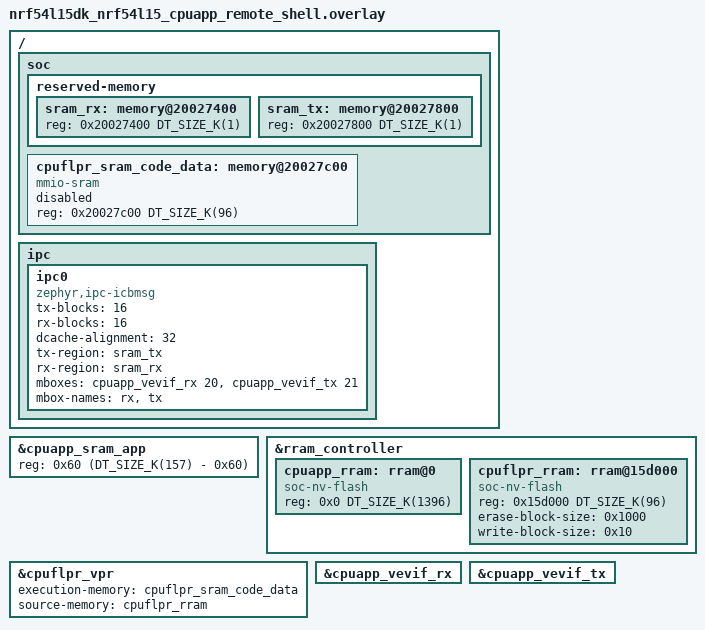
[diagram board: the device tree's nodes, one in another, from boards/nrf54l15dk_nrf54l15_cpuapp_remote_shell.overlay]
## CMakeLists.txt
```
# SPDX-License-Identifier: Apache-2.0

cmake_minimum_required(VERSION 3.28.0)
find_package(Zephyr REQUIRED HINTS $ENV{ZEPHYR_BASE})
project(shell_module)

target_sources(app PRIVATE src/main.c src/test_module.c)
target_sources_ifdef(CONFIG_SHELL_DYNAMIC_CMDS app PRIVATE src/dynamic_cmd.c)
target_sources_ifdef(CONFIG_SHELL_BACKEND_SERIAL app PRIVATE src/uart_reinit.c)
target_sources_ifdef(CONFIG_SHELL_START_OBSCURED app PRIVATE src/login_cmd.c)
```

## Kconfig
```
# Config options for logger sample app

# Copyright (c) 2018 Nordic Semiconductor ASA
# SPDX-License-Identifier: Apache-2.0

mainmenu "Shell module sample application"

menu "Application configuration"

config SHELL_FOREGROUND_CMDS
	bool "Shell foreground commands example"
	default y

config SHELL_DYNAMIC_CMDS
	bool "Shell dynamic commands example"
	default y

endmenu

source "Kconfig.zephyr"
```

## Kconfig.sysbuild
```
#
# Copyright (c) 2026 Nordic Semiconductor ASA
#
# SPDX-License-Identifier: Apache-2.0
#

config REMOTE_BOARD
	string
	default "$(BOARD)/nrf5340/cpunet" if BOARD_NRF5340DK_NRF5340_CPUAPP
	default "$(BOARD)/nrf5340/cpunet" if BOARD_NRF5340BSIM_NRF5340_CPUAPP
	default "$(BOARD)/nrf54h20/cpurad" if BOARD_NRF54H20DK_NRF54H20_CPUAPP
	default "$(BOARD)/nrf54l15/cpuflpr" if BOARD_NRF54L15DK_NRF54L15_CPUAPP

source "share/sysbuild/Kconfig"
```

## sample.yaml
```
sample:
  name: Shell Sample
tests:
  sample.shell.shell_module:
    platform_exclude: qemu_rx
    filter: CONFIG_SERIAL and dt_chosen_enabled("zephyr,shell-uart")
    tags: shell
    harness: shell
    min_ram: 40
    integration_platforms:
      - native_sim
    extra_configs:
      - arch:posix:CONFIG_UART_NATIVE_PTY_0_ON_STDINOUT=y
      - platform:iotdk/arc_iot:CONFIG_ARC_IOT_CUSTOM_CPU_IDLE=y
  sample.shell.shell_module.usb:
    depends_on: usbd
    tags:
      - shell
      - usb
    harness: keyboard
    min_ram: 40
    extra_args:
      - EXTRA_CONF_FILE="overlay-usb.conf"
      - DTC_OVERLAY_FILE="usb.overlay"
    integration_platforms:
      - frdm_k64f
  sample.shell.shell_module.minimal:
    filter: CONFIG_SERIAL and dt_chosen_enabled("zephyr,shell-uart")
    tags: shell
    harness: keyboard
    extra_args: CONF_FILE="prj_minimal.conf"
    integration_platforms:
      - native_sim
  sample.shell.shell_module.getopt:
    integration_platforms:
      - qemu_x86
    arch_exclude: posix
    filter: CONFIG_SERIAL and dt_chosen_enabled("zephyr,shell-uart") and not CONFIG_NEWLIB_LIBC
    tags: shell
    harness: keyboard
    min_ram: 40
    extra_args: CONF_FILE="prj_getopt.conf"
  sample.shell.shell_module.minimal_rtt:
    filter: CONFIG_HAS_SEGGER_RTT
    tags: shell
    harness: keyboard
    extra_args: CONF_FILE="prj_minimal_rtt.conf"
    integration_platforms:
      - nrf52833dk/nrf52833
  sample.shell.shell_module.bt:
    platform_allow:
      - nrf52840dk/nrf52840
    integration_platforms:
      - nrf52840dk/nrf52840
    tags:
      - shell
      - bluetooth
    filter: CONFIG_DT_HAS_ZEPHYR_NUS_UART_ENABLED
    harness: bluetooth_nus
    arch_exclude:
      - posix
    extra_args:
      - EXTRA_CONF_FILE="overlay-bt.conf"
      - DTC_OVERLAY_FILE="bt.overlay"
  sample.shell.shell_module.login:
    filter: CONFIG_SERIAL and dt_chosen_enabled("zephyr,shell-uart")
    tags: shell
    harness: keyboard
    min_ram: 40
    extra_args: CONF_FILE="prj_login.conf"
    integration_platforms:
      - native_sim
  sample.shell.shell_module.robot:
    harness: robot
    harness_config:
      robot_testsuite: shell_module.robot
  sample.shell.shell_module.remote:
    sysbuild: true
    tags:
      - shell
      - ipc
    platform_allow:
      - nrf54l15dk/nrf54l15/cpuapp
      - nrf5340dk/nrf5340/cpuapp
      - nrf5340bsim/nrf5340/cpuapp
      - nrf54h20dk/nrf54h20/cpuapp
    harness: shell
    harness_config:
      shell_commands_file: test_remote_shell.yml
    integration_platforms:
      - nrf5340bsim/nrf5340/cpuapp
    extra_configs:
      - CONFIG_IPC_SERVICE=y
      - CONFIG_MBOX=y
      - CONFIG_SHELL_REMOTE=y
      - CONFIG_PBUF_RX_READ_BUF_SIZE=256
      - CONFIG_HEAP_MEM_POOL_SIZE=1024
    extra_args:
      - FILE_SUFFIX=remote_shell
```

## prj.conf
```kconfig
CONFIG_PRINTK=y
CONFIG_SHELL=y
CONFIG_LOG=y
CONFIG_LOG_CMDS=y
CONFIG_INIT_STACKS=y
CONFIG_THREAD_STACK_INFO=y
CONFIG_KERNEL_SHELL=y
CONFIG_THREAD_MONITOR=y
CONFIG_BOOT_BANNER=n
CONFIG_THREAD_NAME=y
CONFIG_DEVICE_SHELL=y
CONFIG_DATE_SHELL=y
CONFIG_THREAD_RUNTIME_STATS=y
CONFIG_THREAD_RUNTIME_STATS_USE_TIMING_FUNCTIONS=y
CONFIG_STATS=y
CONFIG_STATS_SHELL=y
```

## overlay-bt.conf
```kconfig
CONFIG_SERIAL=y
CONFIG_CONSOLE=y
CONFIG_UART_CONSOLE=y

CONFIG_BT=y
CONFIG_BT_PERIPHERAL=y
CONFIG_BT_ZEPHYR_NUS=y
CONFIG_UART_BT=y
CONFIG_BT_ZEPHYR_NUS_AUTO_START_BLUETOOTH=y

# Bluetooth optimizations to allow larger data packets.
CONFIG_BT_RX_STACK_SIZE=2048
CONFIG_BT_L2CAP_TX_MTU=512
CONFIG_BT_BUF_ACL_RX_SIZE=502
CONFIG_BT_BUF_ACL_TX_SIZE=502
CONFIG_BT_CTLR_DATA_LENGTH_MAX=251
```

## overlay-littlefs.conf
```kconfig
CONFIG_FLASH=y
CONFIG_FLASH_MAP=y
CONFIG_FLASH_PAGE_LAYOUT=y

CONFIG_FILE_SYSTEM=y
CONFIG_FILE_SYSTEM_LITTLEFS=y
CONFIG_FILE_SYSTEM_SHELL=y
CONFIG_HEAP_MEM_POOL_SIZE=16384
```

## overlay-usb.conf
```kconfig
CONFIG_USB_DEVICE_STACK_NEXT=y
CONFIG_CDC_ACM_SERIAL_INITIALIZE_AT_BOOT=y
CONFIG_CDC_ACM_SERIAL_PRODUCT_STRING="Zephyr USB shell sample"
CONFIG_SHELL_BACKEND_SERIAL_CHECK_DTR=y
CONFIG_USBD_CDC_ACM_LOG_LEVEL_OFF=y
CONFIG_UART_LINE_CTRL=y
CONFIG_LOG_DEFAULT_LEVEL=1
```

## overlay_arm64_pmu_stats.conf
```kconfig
# SPDX-License-Identifier: Apache-2.0
#
# ARM64 PMU perf + SMP scheduler stats + PMU overflow sampling for shell_module.
#
# Build (from $ZEPHYR_BASE):
#
#   west build -p always -b versalnet_apu samples/subsys/shell/shell_module \
#     -- -DEXTRA_CONF_FILE=overlay_arm64_pmu_stats.conf
#
# Shell commands:
#   sched cpus | sched threads | sched top [-c cpu] [-d] [-i ms]
#   perf list | perf start [-e ev] | perf stop | perf report
#   perf record start [-e ev] [-f Hz] [-t sec] | stop | dump | export | clear

CONFIG_SHELL_BACKEND_SERIAL=y
CONFIG_MAIN_STACK_SIZE=4096
CONFIG_SHELL_STACK_SIZE=4096

# Prevent deferred log messages from crashing the logging thread via the
# shell log backend's cbprintf path on SMP.  With LOG_MODE_DEFERRED (the
# default) and SHELL_LOG_BACKEND, the logging thread can corrupt its own
# saved LR with the uart device's .rodata address when processing messages
# that include 64-bit format args.  Immediate mode prints synchronously on
# the calling thread and avoids the logging thread entirely.
CONFIG_LOG_MODE_IMMEDIATE=y

CONFIG_ARM64_PMUV3=y
CONFIG_PERF_SHELL=y

CONFIG_PROFILING=y
CONFIG_PROFILING_PMU_SAMPLING=y

CONFIG_THREAD_RUNTIME_STATS=y
CONFIG_SCHED_THREAD_USAGE=y
CONFIG_SCHED_THREAD_USAGE_ALL=y
CONFIG_SCHED_THREAD_USAGE_AUTO_ENABLE=y
CONFIG_THREAD_MONITOR=y
CONFIG_THREAD_NAME=y
CONFIG_SCHED_STATS_SHELL=y

CONFIG_SMP=y
CONFIG_SCHED_CPU_MASK=y
```

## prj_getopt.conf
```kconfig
CONFIG_PRINTK=y
CONFIG_SHELL=y
CONFIG_SHELL_GETOPT=y
CONFIG_LOG=y
CONFIG_INIT_STACKS=y
CONFIG_THREAD_STACK_INFO=y
CONFIG_KERNEL_SHELL=y
CONFIG_THREAD_MONITOR=y
CONFIG_BOOT_BANNER=n
CONFIG_THREAD_NAME=y
CONFIG_DEVICE_SHELL=y
CONFIG_DATE_SHELL=y
CONFIG_THREAD_RUNTIME_STATS=y
```

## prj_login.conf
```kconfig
CONFIG_PRINTK=y
CONFIG_SHELL=y
CONFIG_LOG=y
CONFIG_INIT_STACKS=y
CONFIG_THREAD_STACK_INFO=y
CONFIG_KERNEL_SHELL=y
CONFIG_THREAD_MONITOR=y
CONFIG_BOOT_BANNER=n
CONFIG_THREAD_NAME=y
CONFIG_DEVICE_SHELL=y
CONFIG_DATE_SHELL=y
CONFIG_THREAD_RUNTIME_STATS=y

CONFIG_SHELL_CMDS_SELECT=y
CONFIG_SHELL_START_OBSCURED=y
CONFIG_SHELL_PROMPT_UART="login: "
CONFIG_SHELL_CMD_ROOT="login"
```

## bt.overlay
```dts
/*
 * Copyright (c) 2024 Croxel, Inc.
 *
 * SPDX-License-Identifier: Apache-2.0
 */

/ {
	chosen {
		zephyr,console = &bt_nus_console_uart;
		zephyr,shell-uart = &bt_nus_console_uart;
	};

	bt_nus_console_uart: bt_nus_console_uart {
		compatible = "zephyr,nus-uart";
		rx-fifo-size = <1024>;
		tx-fifo-size = <1024>;
	};
};
```

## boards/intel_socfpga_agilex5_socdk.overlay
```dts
/*
 * Copyright (C) 2023 Intel Corporation
 * SPDX-License-Identifier: Apache-2.0
 */

/*
 * The overlay file should be used to enable any
 * dts nodes required by this shell application for this
 * board.
 *
 * Nothing here as of now.
 */

&timer0 {
	status = "okay";
};

&timer1 {
	status = "okay";
};

&timer2 {
	status = "okay";
};

&timer3 {
	status = "okay";
};

&sip_smc {
	zephyr,num-clients = <2>;
	status = "okay";
};

&sdmmc {
	status = "okay";
};
```

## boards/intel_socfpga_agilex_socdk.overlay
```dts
/*
 * Copyright (C) 2023 Intel Corporation
 * SPDX-License-Identifier: Apache-2.0
 */

/*
 * The overlay file should be used to enable any
 * dts nodes required by this shell application for this
 * board.
 */

&sip_smc {
	zephyr,num-clients = <2>;
	status = "okay";
};
```

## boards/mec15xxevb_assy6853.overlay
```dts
/ {
    chosen {
        zephyr,console = &uart2;
        zephyr,shell-uart = &uart2;
    };
};
```

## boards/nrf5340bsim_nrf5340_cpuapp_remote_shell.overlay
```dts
/*
 * Copyright (c) 2026 Nordic Semiconductor ASA
 *
 * SPDX-License-Identifier: Apache-2.0
 */

#include "nrf5340dk_nrf5340_cpuapp_remote_shell.overlay"

/ {
	chosen {
		zephyr,console = &uart0;
		zephyr,shell-uart = &uart0;
	};
};

&uart0 {
	compatible = "zephyr,native-pty-uart";
	status = "okay";
	/delete-property/ pinctrl-0;
	/delete-property/ pinctrl-1;
	/delete-property/ pinctrl-names;
};
```

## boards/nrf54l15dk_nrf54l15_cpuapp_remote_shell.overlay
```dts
/*
 * Copyright (c) 2026 Nordic Semiconductor ASA
 *
 * SPDX-License-Identifier: Apache-2.0
 */

/* 256k RAM layout:
 *  - 157k APP RAM
 *  - 2k APP-FLPR IPC communication
 *  - 96k FLPR Code
 *  - 1k FLPR Hibernation space
 */

/ {
	soc {
		reserved-memory {
			#address-cells = <1>;
			#size-cells = <1>;

			sram_rx: memory@20027400 {
				reg = <0x20027400 DT_SIZE_K(1)>;
			};

			sram_tx: memory@20027800 {
				reg = <0x20027800 DT_SIZE_K(1)>;
			};
		};

		cpuflpr_sram_code_data: memory@20027c00 {
			compatible = "mmio-sram";
			reg = <0x20027c00 DT_SIZE_K(96)>;
			ranges = <0x0 0x20027c00 DT_SIZE_K(96)>;
			status = "reserved";
			#address-cells = <1>;
			#size-cells = <1>;
		};
	};

	ipc {
		ipc0: ipc0 {
			compatible = "zephyr,ipc-icbmsg";
			tx-blocks = <16>;
			rx-blocks = <16>;
			dcache-alignment = <32>;
			tx-region = <&sram_tx>;
			rx-region = <&sram_rx>;
			mboxes = <&cpuapp_vevif_rx 20>, <&cpuapp_vevif_tx 21>;
			mbox-names = "rx", "tx";
			status = "okay";
		};
	};
};

&cpuapp_sram_app {
	reg = <0x60 (DT_SIZE_K(157) - 0x60)>;
};

&rram_controller {
	cpuapp_rram: rram@0 {
		compatible = "soc-nv-flash";
		reg = <0x0 DT_SIZE_K(1396)>;
		ranges = <0x0 0 DT_SIZE_K(1396)>;
	};

	cpuflpr_rram: rram@15d000 {
		compatible = "soc-nv-flash";
		reg = <0x15d000 DT_SIZE_K(96)>;
		ranges = <0x0 0x15d000 DT_SIZE_K(96)>;
		erase-block-size = <0x1000>;
		write-block-size = <0x10>;
		#address-cells = <1>;
		#size-cells = <1>;
	};
};

&cpuflpr_vpr {
	status = "okay";
	execution-memory = <&cpuflpr_sram_code_data>;
	source-memory = <&cpuflpr_rram>;
};

&cpuapp_vevif_rx {
	status = "okay";
};

&cpuapp_vevif_tx {
	status = "okay";
};
```

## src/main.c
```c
/*
 * Copyright (c) 2015 Intel Corporation
 *
 * SPDX-License-Identifier: Apache-2.0
 */

#include <zephyr/kernel.h>
#include <zephyr/shell/shell.h>
#include <zephyr/version.h>
#include <zephyr/logging/log.h>
#include <stdlib.h>
#include <zephyr/drivers/uart.h>
#include <ctype.h>

LOG_MODULE_REGISTER(app);

extern void foo(void);

void timer_expired_handler(struct k_timer *timer)
{
	LOG_INF("Timer expired.");

	/* Call another module to present logging from multiple sources. */
	foo();
}

K_TIMER_DEFINE(log_timer, timer_expired_handler, NULL);

static int cmd_log_test_start(const struct shell *sh, size_t argc,
			      char **argv, uint32_t period)
{
	ARG_UNUSED(argv);

	k_timer_start(&log_timer, K_MSEC(period), K_MSEC(period));
	shell_print(sh, "Log test started\n");

	return 0;
}

static int cmd_log_test_start_demo(const struct shell *sh, size_t argc,
				   char **argv)
{
	return cmd_log_test_start(sh, argc, argv, 200);
}

static int cmd_log_test_start_flood(const struct shell *sh, size_t argc,
				    char **argv)
{
	return cmd_log_test_start(sh, argc, argv, 10);
}

static int cmd_log_test_stop(const struct shell *sh, size_t argc,
			     char **argv)
{
	ARG_UNUSED(argc);
	ARG_UNUSED(argv);

	k_timer_stop(&log_timer);
	shell_print(sh, "Log test stopped");

	return 0;
}

SHELL_STATIC_SUBCMD_SET_CREATE(sub_log_test_start,
	SHELL_CMD_ARG(demo, NULL,
		  "Start log timer which generates log message every 200ms.",
		  cmd_log_test_start_demo, 1, 0),
	SHELL_CMD_ARG(flood, NULL,
		  "Start log timer which generates log message every 10ms.",
		  cmd_log_test_start_flood, 1, 0),
	SHELL_SUBCMD_SET_END /* Array terminated. */
);
SHELL_STATIC_SUBCMD_SET_CREATE(sub_log_test,
	SHELL_CMD_ARG(start, &sub_log_test_start, "Start log test", NULL, 2, 0),
	SHELL_CMD_ARG(stop, NULL, "Stop log test.", cmd_log_test_stop, 1, 0),
	SHELL_SUBCMD_SET_END /* Array terminated. */
);

SHELL_CMD_REGISTER(log_test, &sub_log_test, "Log test", NULL);

static int cmd_demo_ping(const struct shell *sh, size_t argc, char **argv)
{
	ARG_UNUSED(argc);
	ARG_UNUSED(argv);

	shell_print(sh, "pong");

	return 0;
}

static int cmd_demo_board(const struct shell *sh, size_t argc, char **argv)
{
	ARG_UNUSED(argc);
	ARG_UNUSED(argv);

	shell_print(sh, CONFIG_BOARD);

	return 0;
}

#if defined CONFIG_SHELL_GETOPT
/* Thread save usage */
static int cmd_demo_getopt_ts(const struct shell *sh, size_t argc,
			      char **argv)
{
	struct sys_getopt_state *state;
	char *cvalue = NULL;
	int aflag = 0;
	int bflag = 0;
	int c;

	while ((c = sys_getopt(argc, argv, "abhc:")) != -1) {
		state = sys_getopt_state_get();
		switch (c) {
		case 'a':
			aflag = 1;
			break;
		case 'b':
			bflag = 1;
			break;
		case 'c':
			cvalue = state->optarg;
			break;
		case 'h':
			/* When getopt is active shell is not parsing
			 * command handler to print help message. It must
			 * be done explicitly.
			 */
			shell_help(sh);
			return SHELL_CMD_HELP_PRINTED;
		case '?':
			if (state->optopt == 'c') {
				shell_print(sh,
					"Option -%c requires an argument.",
					state->optopt);
			} else if (isprint(state->optopt) != 0) {
				shell_print(sh,
					"Unknown option `-%c'.",
					state->optopt);
			} else {
				shell_print(sh,
					"Unknown option character `\\x%x'.",
					state->optopt);
			}
			return 1;
		default:
			break;
		}
	}

	shell_print(sh, "aflag = %d, bflag = %d", aflag, bflag);
	return 0;
}

static int cmd_demo_getopt(const struct shell *sh, size_t argc,
			      char **argv)
{
	char *cvalue = NULL;
	int aflag = 0;
	int bflag = 0;
	int c;

	while ((c = sys_getopt(argc, argv, "abhc:")) != -1) {
		switch (c) {
		case 'a':
			aflag = 1;
			break;
		case 'b':
			bflag = 1;
			break;
		case 'c':
			cvalue = sys_getopt_optarg;
			break;
		case 'h':
			/* When getopt is active shell is not parsing
			 * command handler to print help message. It must
			 * be done explicitly.
			 */
			shell_help(sh);
			return SHELL_CMD_HELP_PRINTED;
		case '?':
			if (sys_getopt_optopt == 'c') {
				shell_print(sh,
					"Option -%c requires an argument.",
					sys_getopt_optopt);
			} else if (isprint(sys_getopt_optopt) != 0) {
				shell_print(sh, "Unknown option `-%c'.",
					    sys_getopt_optopt);
			} else {
				shell_print(sh,
					"Unknown option character `\\x%x'.",
					sys_getopt_optopt);
			}
			return 1;
		default:
			break;
		}
	}

	shell_print(sh, "aflag = %d, bflag = %d", aflag, bflag);
	return 0;
}
#endif

static int cmd_demo_params(const struct shell *sh, size_t argc, char **argv)
{
	shell_print(sh, "argc = %zd", argc);
	for (size_t cnt = 0; cnt < argc; cnt++) {
		shell_print(sh, "  argv[%zd] = %s", cnt, argv[cnt]);
	}

	return 0;
}

static int cmd_demo_hexdump(const struct shell *sh, size_t argc, char **argv)
{
	shell_print(sh, "argc = %zd", argc);
	for (size_t cnt = 0; cnt < argc; cnt++) {
		shell_print(sh, "argv[%zd]", cnt);
		shell_hexdump(sh, (const uint8_t *)argv[cnt], strlen(argv[cnt]));
	}

	return 0;
}

static int cmd_version(const struct shell *sh, size_t argc, char **argv)
{
	ARG_UNUSED(argc);
	ARG_UNUSED(argv);

	shell_print(sh, "Zephyr version %s", KERNEL_VERSION_STRING);

	return 0;
}

static int set_bypass(const struct shell *sh, shell_bypass_cb_t bypass)
{
	static bool in_use;

	if (bypass && in_use) {
		shell_error(sh, "Sample supports setting bypass on single instance.");

		return -EBUSY;
	}

	in_use = !in_use;
	if (in_use) {
		shell_print(sh, "Bypass started, press ctrl-x ctrl-q to escape");
		in_use = true;
	}

	shell_set_bypass(sh, bypass, NULL);

	return 0;
}

#define CHAR_1 0x18
#define CHAR_2 0x11

static void bypass_cb(const struct shell *sh, uint8_t *data, size_t len, void *user_data)
{
	static uint8_t tail;
	bool escape = false;

	ARG_UNUSED(user_data);

	/* Check if escape criteria is met. */
	if (tail == CHAR_1 && data[0] == CHAR_2) {
		escape = true;
	} else {
		for (int i = 0; i < (len - 1); i++) {
			if (data[i] == CHAR_1 && data[i + 1] == CHAR_2) {
				escape = true;
				break;
			}
		}
	}

	if (escape) {
		shell_print(sh, "Exit bypass");
		set_bypass(sh, NULL);
		tail = 0;
		return;
	}

	/* Store last byte for escape sequence detection */
	tail = data[len - 1];

	/* Do the data processing. */
	for (int i = 0; i < len; i++) {
		shell_fprintf(sh, SHELL_INFO, "%02x ", data[i]);
	}
	shell_fprintf(sh, SHELL_INFO, "| ");

	for (int i = 0; i < len; i++) {
		shell_fprintf(sh, SHELL_INFO, "%c", data[i]);
	}
	shell_fprintf(sh, SHELL_INFO, "\n");

}

static int cmd_bypass(const struct shell *sh, size_t argc, char **argv)
{
	return set_bypass(sh, bypass_cb);
}

static int cmd_demo_readline(const struct shell *sh, size_t argc, char **argv)
{
	uint8_t input_buf[256];
	int ret;

	if (argc == 2 && strcmp(argv[1], "obscured") == 0) {
		shell_obscure_set(sh, true);
	}

	shell_readline_prompt_set(sh, "Input: ");
	ret = shell_readline(sh, input_buf, sizeof(input_buf), K_SECONDS(10));
	shell_obscure_set(sh, false);

	if (ret < 0) {
		shell_error(sh, "Input error (%d)", ret);
		return ret;
	}

	shell_print(sh, "Got %d characters:", ret);
	shell_hexdump(sh, input_buf, ret);

	return 0;
}

static int cmd_dict(const struct shell *sh, size_t argc, char **argv,
		    void *data)
{
	int val = (intptr_t)data;

	shell_print(sh, "(syntax, value) : (%s, %d)", argv[0], val);

	return 0;
}

SHELL_SUBCMD_DICT_SET_CREATE(sub_dict_cmds, cmd_dict,
	(value_0, 0, "value 0"), (value_1, 1, "value 1"),
	(value_2, 2, "value 2"), (value_3, 3, "value 3")
);

SHELL_STATIC_SUBCMD_SET_CREATE(sub_demo,
	SHELL_CMD(dictionary, &sub_dict_cmds, "Dictionary commands", NULL),
	SHELL_CMD(hexdump, NULL, "Hexdump params command.", cmd_demo_hexdump),
	SHELL_CMD(params, NULL, "Print params command.", cmd_demo_params),
	SHELL_CMD(ping, NULL, "Ping command.", cmd_demo_ping),
	SHELL_CMD(board, NULL, "Show board name command.", cmd_demo_board),
	SHELL_COND_CMD_ARG(COND_CODE_1(CONFIG_SHELL_REMOTE_CLI, (0), (1)),
			readline, NULL, SHELL_HELP("Read user input", "[obscured]"),
		      cmd_demo_readline, 1, 1),
#if defined CONFIG_SHELL_GETOPT
	SHELL_CMD(getopt_thread_safe, NULL,
		  "Command using getopt in thread safe way"
		  " looking for: \"abhc:\".",
		  cmd_demo_getopt_ts),
	SHELL_CMD(getopt, NULL, "Command using getopt in non thread safe way"
		  " looking for: \"abhc:\".\n", cmd_demo_getopt),
#endif
	SHELL_SUBCMD_SET_END /* Array terminated. */
);
SHELL_CMD_REGISTER(demo, &sub_demo, "Demo commands", NULL);

SHELL_CMD_ARG_REGISTER(version, NULL, "Show kernel version", cmd_version, 1, 0);

SHELL_COND_CMD_ARG_REGISTER(COND_CODE_1(CONFIG_SHELL_REMOTE_CLI, (0), (1)),
			bypass, NULL, "Bypass shell", cmd_bypass, 1, 0);

/* Create a set of commands. Commands to this set are added using @ref SHELL_SUBCMD_ADD
 * and @ref SHELL_SUBCMD_COND_ADD.
 */
SHELL_SUBCMD_SET_CREATE(sub_section_cmd, (section_cmd));

static int cmd1_handler(const struct shell *sh, size_t argc, char **argv)
{
	ARG_UNUSED(sh);
	ARG_UNUSED(argc);
	ARG_UNUSED(argv);

	shell_print(sh, "cmd1 executed");

	return 0;
}

/* Create a set of subcommands for "section_cmd cm1". */
SHELL_SUBCMD_SET_CREATE(sub_section_cmd1, (section_cmd, cmd1));

/* Add command to the set. Subcommand set is identify by parent shell command. */
SHELL_SUBCMD_ADD((section_cmd), cmd1, &sub_section_cmd1, "help for cmd1", cmd1_handler, 1, 0);

SHELL_CMD_REGISTER(section_cmd, &sub_section_cmd,
		   "Demo command using section for subcommand registration", NULL);

int main(void)
{
#if DT_NODE_HAS_COMPAT(DT_CHOSEN(zephyr_shell_uart), zephyr_cdc_acm_uart)
	const struct device *dev;
	uint32_t dtr = 0;

	dev = DEVICE_DT_GET(DT_CHOSEN(zephyr_shell_uart));
	if (!device_is_ready(dev)) {
		return 0;
	}

	while (!dtr) {
		uart_line_ctrl_get(dev, UART_LINE_CTRL_DTR, &dtr);
		k_sleep(K_MSEC(100));
	}
#endif
	return 0;
}
```

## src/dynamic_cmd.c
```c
/*
 * Copyright (c) 2018 Nordic Semiconductor ASA
 *
 * SPDX-License-Identifier: Apache-2.0
 */

#include <zephyr/shell/shell.h>
#include <ctype.h>
#include <stdio.h>
#include <stdlib.h>

#define MAX_CMD_CNT (20u)
#define MAX_CMD_LEN (33u)

/* buffer holding dynamically created user commands */
static char dynamic_cmd_buffer[MAX_CMD_CNT][MAX_CMD_LEN];
/* commands counter */
static uint8_t dynamic_cmd_cnt;

typedef int cmp_t(const void *, const void *);
extern void qsort(void *a, size_t n, size_t es, cmp_t *cmp);

/* function required by qsort */
static int string_cmp(const void *p_a, const void *p_b)
{
	return strcmp((const char *)p_a, (const char *)p_b);
}

static int cmd_dynamic_add(const struct shell *sh,
			   size_t argc, char **argv)
{
	uint16_t cmd_len;
	uint8_t idx;

	ARG_UNUSED(argc);

	if (dynamic_cmd_cnt >= MAX_CMD_CNT) {
		shell_error(sh, "command limit reached");
		return -ENOEXEC;
	}

	cmd_len = strlen(argv[1]);

	if (cmd_len >= MAX_CMD_LEN) {
		shell_error(sh, "too long command");
		return -ENOEXEC;
	}

	for (idx = 0U; idx < cmd_len; idx++) {
		if (isalnum((int)(argv[1][idx])) == 0) {
			shell_error(sh,
				    "bad command name - please use only"
				    " alphanumerical characters");
			return -ENOEXEC;
		}
	}

	for (idx = 0U; idx < MAX_CMD_CNT; idx++) {
		if (!strcmp(dynamic_cmd_buffer[idx], argv[1])) {
			shell_error(sh, "duplicated command");
			return -ENOEXEC;
		}
	}

	sprintf(dynamic_cmd_buffer[dynamic_cmd_cnt++], "%s", argv[1]);

	qsort(dynamic_cmd_buffer, dynamic_cmd_cnt,
	      sizeof(dynamic_cmd_buffer[0]), string_cmp);

	shell_print(sh, "command added successfully");

	return 0;
}

static int cmd_dynamic_execute(const struct shell *sh,
			       size_t argc, char **argv)
{
	ARG_UNUSED(argc);
	ARG_UNUSED(argv);

	for (uint8_t idx = 0; idx <  dynamic_cmd_cnt; idx++) {
		if (!strcmp(dynamic_cmd_buffer[idx], argv[1])) {
			shell_print(sh, "dynamic command: %s", argv[1]);
			return 0;
		}
	}

	shell_error(sh, "%s: unknown parameter: %s", argv[0], argv[1]);

	return -ENOEXEC;
}

static int cmd_dynamic_remove(const struct shell *sh, size_t argc,
			      char **argv)
{
	ARG_UNUSED(argc);
	ARG_UNUSED(argv);

	for (uint8_t idx = 0; idx <  dynamic_cmd_cnt; idx++) {
		if (!strcmp(dynamic_cmd_buffer[idx], argv[1])) {
			if (idx == MAX_CMD_CNT - 1) {
				dynamic_cmd_buffer[idx][0] = '\0';
			} else {
				memmove(dynamic_cmd_buffer[idx],
					dynamic_cmd_buffer[idx + 1],
					sizeof(dynamic_cmd_buffer[idx]) *
					(dynamic_cmd_cnt - idx));
			}

			--dynamic_cmd_cnt;
			shell_print(sh, "command removed successfully");
			return 0;
		}
	}
	shell_error(sh, "did not find command: %s", argv[1]);

	return -ENOEXEC;
}

static int cmd_dynamic_show(const struct shell *sh,
			    size_t argc, char **argv)
{
	ARG_UNUSED(argc);
	ARG_UNUSED(argv);

	if (dynamic_cmd_cnt == 0U) {
		shell_warn(sh, "Please add some commands first.");
		return -ENOEXEC;
	}

	shell_print(sh, "Dynamic command list:");

	for (uint8_t i = 0; i < dynamic_cmd_cnt; i++) {
		shell_print(sh, "[%3d] %s", i, dynamic_cmd_buffer[i]);
	}

	return 0;
}

/* dynamic command creation */
static void dynamic_cmd_get(size_t idx, struct shell_static_entry *entry)
{
	if (idx < dynamic_cmd_cnt) {
		/* m_dynamic_cmd_buffer must be sorted alphabetically to ensure
		 * correct CLI completion
		 */
		entry->syntax = dynamic_cmd_buffer[idx];
		entry->handler  = NULL;
		entry->subcmd = NULL;
		entry->help = "Show dynamic command name.";
	} else {
		/* if there are no more dynamic commands available syntax
		 * must be set to NULL.
		 */
		entry->syntax = NULL;
	}
}

SHELL_DYNAMIC_CMD_CREATE(m_sub_dynamic_set, dynamic_cmd_get);
SHELL_STATIC_SUBCMD_SET_CREATE(m_sub_dynamic,
	SHELL_CMD_ARG(add, NULL,
		"Add a new dynamic command.\nExample usage: [ dynamic add test "
		"] will add a dynamic command 'test'.\nIn this example, command"
		" name length is limited to 32 chars. You can add up to 20"
		" commands. Commands are automatically sorted to ensure correct"
		" shell completion.",
		cmd_dynamic_add, 2, 0),
	SHELL_CMD_ARG(execute, &m_sub_dynamic_set,
		"Execute a command.", cmd_dynamic_execute, 2, 0),
	SHELL_CMD_ARG(remove, &m_sub_dynamic_set,
		"Remove a command.", cmd_dynamic_remove, 2, 0),
	SHELL_CMD_ARG(show, NULL,
		"Show all added dynamic commands.", cmd_dynamic_show, 1, 0),
	SHELL_SUBCMD_SET_END
);

SHELL_CMD_REGISTER(dynamic, &m_sub_dynamic,
		   "Demonstrate dynamic command usage.", NULL);
```

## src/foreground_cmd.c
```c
/*
 * Copyright (c) 2018 Nordic Semiconductor ASA
 *
 * SPDX-License-Identifier: Apache-2.0
 */

#include <shell/shell.h>
#include <zephyr.h>

#define FOREGROUND_TIMER_HELP \
	"Demo command showing printing to shell from various contexts"

#define FOREGROUND_TIMER_START_HELP \
	"Start periodic timer. Timer handler prints to shell. CTRL+C" \
	" terminates printing. Timer keeps running in background."

#define FOREGROUND_TIMER_STOP_HELP \
	"Stop timer."

#define FOREGROUND_TIMER_SINGLE_SHOT_HELP \
	"Start single shot timer."

struct timer_work_duo {
	struct k_timer timer;
	struct k_work work;
	const struct shell *shell;
	bool single_shot;
	bool running;
};

static struct timer_work_duo data;

static void timer_expired_work(struct k_work *work)
{
	struct timer_work_duo *data =
			CONTAINER_OF(work, struct timer_work_duo, work);

	shell_print(data->shell, "Timer expired.");

	if (data->single_shot) {
		shell_print(data->shell, "Single shot timer command exits.");
		shell_command_exit(data->shell);
		data->running = false;
	}
}

static void timer_handler(struct k_timer *timer)
{
	struct timer_work_duo *data =
			CONTAINER_OF(timer, struct timer_work_duo, timer);

	k_work_submit(&data->work);
}

static int start_timer(const struct shell *shell, bool single_shot)
{

	if (data.running) {
		shell_error(shell, "Timer is already started.");
		return -ENOEXEC;
	}

	k_timer_init(&data.timer, timer_handler, NULL);
	k_work_init(&data.work, timer_expired_work);
	data.shell = shell;
	data.single_shot = single_shot;
	data.running = true;

	k_timer_start(&data.timer, 1000, single_shot ? 0 : 1000);

	shell_command_enter(shell);

	return 0;

}
static int cmd_fg_timer_start(const struct shell *shell,
			      size_t argc, char **argv)
{
	ARG_UNUSED(argc);
	ARG_UNUSED(argv);

	int err;

	err = start_timer(shell, false);

	if (err == 0) {
		shell_print(shell, "Periodic timer started.");
	}

	return err;
}

static int cmd_fg_timer_single_shot(const struct shell *shell,
				    size_t argc, char **argv)
{
	ARG_UNUSED(argc);
	ARG_UNUSED(argv);

	int err;

	err = start_timer(shell, true);

	if (err == 0) {
		shell_print(shell, "Single shot started.");
	}

	return err;
}

static int cmd_fg_timer_stop(const struct shell *shell,
			      size_t argc, char **argv)
{
	ARG_UNUSED(argc);
	ARG_UNUSED(argv);

	k_timer_stop(&data.timer);
	data.running = false;

	shell_print(shell, "Timer stopped.");

	return 0;
}

SHELL_CREATE_STATIC_SUBCMD_SET(sub_foreground_timer)
{
	/* Alphabetically sorted. */
	SHELL_CMD_ARG(start, NULL, FOREGROUND_TIMER_START_HELP,
			cmd_fg_timer_start, 1, 0),
	SHELL_CMD_ARG(stop, NULL, FOREGROUND_TIMER_STOP_HELP,
			cmd_fg_timer_stop, 1, 0),
	SHELL_CMD_ARG(single_shot, NULL, FOREGROUND_TIMER_SINGLE_SHOT_HELP,
			cmd_fg_timer_single_shot, 1, 0),
	SHELL_SUBCMD_SET_END /* Array terminated. */
};

SHELL_CMD_ARG_REGISTER(foreground_timer, &sub_foreground_timer,
		   FOREGROUND_TIMER_HELP, NULL, 1, 1);
```

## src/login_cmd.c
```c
/*
 * Copyright (c) 2015 Intel Corporation
 *
 * SPDX-License-Identifier: Apache-2.0
 */

#include <zephyr/kernel.h>
#include <zephyr/shell/shell.h>
#include <zephyr/init.h>

#define DEFAULT_PASSWORD "zephyr"

static int login_init(void)
{
	printk("Shell Login Demo\nHint: password = %s\n", DEFAULT_PASSWORD);
	if (!CONFIG_SHELL_CMD_ROOT[0]) {
		shell_set_root_cmd("login");
	}
	return 0;
}

static int check_passwd(char *passwd)
{
	/* example only -- not recommended for production use */
	return strcmp(passwd, DEFAULT_PASSWORD);
}

static int cmd_login(const struct shell *sh, size_t argc, char **argv)
{
	static uint32_t attempts;

	if (check_passwd(argv[1]) != 0) {
		shell_error(sh, "Incorrect password!");
		attempts++;
		if (attempts > 3) {
			k_sleep(K_SECONDS(attempts));
		}
		return -EINVAL;
	}

	/* clear history so password not visible there */
	z_shell_history_purge(sh->history);
	shell_obscure_set(sh, false);
	shell_set_root_cmd(NULL);
	shell_prompt_change(sh, "uart:~$ ");
	shell_print(sh, "Shell Login Demo\n");
	shell_print(sh, "Hit tab for help.\n");
	attempts = 0;
	return 0;
}

static int cmd_logout(const struct shell *sh, size_t argc, char **argv)
{
	shell_set_root_cmd("login");
	shell_obscure_set(sh, true);
	shell_prompt_change(sh, "login: ");
	shell_print(sh, "\n");
	return 0;
}

SHELL_CMD_ARG_REGISTER(login, NULL, "<password>", cmd_login, 2, 0);

SHELL_CMD_REGISTER(logout, NULL, "Log out.", cmd_logout);

SYS_INIT(login_init, APPLICATION, CONFIG_APPLICATION_INIT_PRIORITY);
```

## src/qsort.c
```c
/*-
 * SPDX-License-Identifier: BSD-3-Clause
 *
 * Copyright (c) 1992, 1993
 *	The Regents of the University of California.  All rights reserved.
 *
 * Redistribution and use in source and binary forms, with or without
 * modification, are permitted provided that the following conditions
 * are met:
 * 1. Redistributions of source code must retain the above copyright
 *    notice, this list of conditions and the following disclaimer.
 * 2. Redistributions in binary form must reproduce the above copyright
 *    notice, this list of conditions and the following disclaimer in the
 *    documentation and/or other materials provided with the distribution.
 * 3. Neither the name of the University nor the names of its contributors
 *    may be used to endorse or promote products derived from this software
 *    without specific prior written permission.
 *
 * THIS SOFTWARE IS PROVIDED BY THE REGENTS AND CONTRIBUTORS ``AS IS'' AND
 * ANY EXPRESS OR IMPLIED WARRANTIES, INCLUDING, BUT NOT LIMITED TO, THE
 * IMPLIED WARRANTIES OF MERCHANTABILITY AND FITNESS FOR A PARTICULAR PURPOSE
 * ARE DISCLAIMED.  IN NO EVENT SHALL THE REGENTS OR CONTRIBUTORS BE LIABLE
 * FOR ANY DIRECT, INDIRECT, INCIDENTAL, SPECIAL, EXEMPLARY, OR CONSEQUENTIAL
 * DAMAGES (INCLUDING, BUT NOT LIMITED TO, PROCUREMENT OF SUBSTITUTE GOODS
 * OR SERVICES; LOSS OF USE, DATA, OR PROFITS; OR BUSINESS INTERRUPTION)
 * HOWEVER CAUSED AND ON ANY THEORY OF LIABILITY, WHETHER IN CONTRACT, STRICT
 * LIABILITY, OR TORT (INCLUDING NEGLIGENCE OR OTHERWISE) ARISING IN ANY WAY
 * OUT OF THE USE OF THIS SOFTWARE, EVEN IF ADVISED OF THE POSSIBILITY OF
 * SUCH DAMAGE.
 */

#if defined(LIBC_SCCS) && !defined(lint)
static const char sccsid[] = "@(#)qsort.c	8.1 (Berkeley) 6/4/93";
#endif /* LIBC_SCCS and not lint */
#include <sys/cdefs.h>
#include <stdlib.h>
#include <stdbool.h>

#ifdef I_AM_QSORT_R
typedef int		 cmp_t(void *, const void *, const void *);
#else
typedef int		 cmp_t(const void *, const void *);
#endif
static inline char	*med3(char *, char *, char *, cmp_t *, void *);

#define	MIN(a, b)	((a) < (b) ? a : b)

/*
 * Qsort routine from Bentley & McIlroy's "Engineering a Sort Function".
 */

static inline void
swapfunc(char *a, char *b, size_t es)
{
	char t;

	do {
		t = *a;
		*a++ = *b;
		*b++ = t;
	} while (--es > 0);
}

#define	vecswap(a, b, n)			\
	do {					\
		if ((n) > 0) {			\
			swapfunc(a, b, n);	\
		}				\
	} while (false)

#ifdef I_AM_QSORT_R
#define	CMP(t, x, y) (cmp((t), (x), (y)))
#else
#define	CMP(t, x, y) (cmp((x), (y)))
#endif

static inline char *
med3(char *a, char *b, char *c, cmp_t *cmp, void *thunk)
{
	return CMP(thunk, a, b) < 0 ?
	       (CMP(thunk, b, c) < 0 ? b : (CMP(thunk, a, c) < 0 ? c : a))
	      : (CMP(thunk, b, c) > 0 ? b : (CMP(thunk, a, c) < 0 ? a : c));
}

#ifdef I_AM_QSORT_R
void qsort_r(void *a, size_t n, size_t es, void *thunk, cmp_t *cmp)
#else
#define	thunk NULL
void qsort(void *a, size_t n, size_t es, cmp_t *cmp)
#endif
{
	char *pa, *pb, *pc, *pd, *pl, *pm, *pn;
	size_t d1, d2;
	int cmp_result;
	int swap_cnt;

loop:
	swap_cnt = 0;
	if (n < 7) {
		for (pm = (char *)a + es; pm < (char *)a + n * es; pm += es) {
			for (pl = pm;
			     pl > (char *)a && CMP(thunk, pl - es, pl) > 0;
			     pl -= es) {
				swapfunc(pl, pl - es, es);
			}
		}
		return;
	}
	pm = (char *)a + (n / 2) * es;
	if (n > 7) {
		pl = a;
		pn = (char *)a + (n - 1) * es;
		if (n > 40) {
			size_t d = (n / 8) * es;

			pl = med3(pl, pl + d, pl + 2 * d, cmp, thunk);
			pm = med3(pm - d, pm, pm + d, cmp, thunk);
			pn = med3(pn - 2 * d, pn - d, pn, cmp, thunk);
		}
		pm = med3(pl, pm, pn, cmp, thunk);
	}
	swapfunc(a, pm, es);
	pa = pb = (char *)a + es;

	pc = pd = (char *)a + (n - 1) * es;
	for (;;) {
		while (pb <= pc && (cmp_result = CMP(thunk, pb, a)) <= 0) {
			if (cmp_result == 0) {
				swap_cnt = 1;
				swapfunc(pa, pb, es);
				pa += es;
			}
			pb += es;
		}
		while (pb <= pc && (cmp_result = CMP(thunk, pc, a)) >= 0) {
			if (cmp_result == 0) {
				swap_cnt = 1;
				swapfunc(pc, pd, es);
				pd -= es;
			}
			pc -= es;
		}
		if (pb > pc) {
			break;
		}

		swapfunc(pb, pc, es);
		swap_cnt = 1;
		pb += es;
		pc -= es;
	}
	if (swap_cnt == 0) {  /* Switch to insertion sort */
		for (pm = (char *)a + es; pm < (char *)a + n * es; pm += es) {
			for (pl = pm;
			     pl > (char *)a && CMP(thunk, pl - es, pl) > 0;
			     pl -= es) {
				swapfunc(pl, pl - es, es);
			}
		}
		return;
	}

	pn = (char *)a + n * es;
	d1 = MIN(pa - (char *)a, pb - pa);
	vecswap(a, pb - d1, d1);
	d1 = MIN(pd - pc, pn - pd - es);
	vecswap(pb, pn - d1, d1);

	d1 = pb - pa;
	d2 = pd - pc;
	if (d1 <= d2) {
		/* Recurse on left partition, then iterate on right partition */
		if (d1 > es) {
#ifdef I_AM_QSORT_R
			qsort_r(a, d1 / es, es, thunk, cmp);
#else
			qsort(a, d1 / es, es, cmp);
#endif
		}
		if (d2 > es) {
			/* Iterate rather than recurse to save stack space */
			/* qsort(pn - d2, d2 / es, es, cmp); */
			a = pn - d2;
			n = d2 / es;
			goto loop;
		}
	} else {
		/* Recurse on right partition, then iterate on left partition */
		if (d2 > es) {
#ifdef I_AM_QSORT_R
			qsort_r(pn - d2, d2 / es, es, thunk, cmp);
#else
			qsort(pn - d2, d2 / es, es, cmp);
#endif
		}
		if (d1 > es) {
			/* Iterate rather than recurse to save stack space */
			/* qsort(a, d1 / es, es, cmp); */
			n = d1 / es;
			goto loop;
		}
	}
}
```

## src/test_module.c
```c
/*
 * Copyright (c) 2018 Nordic Semiconductor ASA
 *
 * SPDX-License-Identifier: Apache-2.0
 */

#include <zephyr/logging/log.h>
#include <zephyr/shell/shell.h>
LOG_MODULE_REGISTER(app_test);

void foo(void)
{
	LOG_INF("info message");
	LOG_WRN("warning message");
	LOG_ERROR("err message");
}

/* Commands below are added using memory section approach which allows to build
 * a set of subcommands from multiple files.
 */
static int cmd2_handler(const struct shell *sh, size_t argc, char **argv)
{
	ARG_UNUSED(sh);
	ARG_UNUSED(argc);
	ARG_UNUSED(argv);

	shell_print(sh, "cmd2 executed");

	return 0;
}

SHELL_SUBCMD_ADD((section_cmd), cmd2, NULL, "help for cmd2", cmd2_handler, 1, 0);

static int sub_cmd1_handler(const struct shell *sh, size_t argc, char **argv)
{
	ARG_UNUSED(sh);
	ARG_UNUSED(argc);
	ARG_UNUSED(argv);

	shell_print(sh, "sub cmd1 executed");

	return 0;
}

SHELL_SUBCMD_COND_ADD(1, (section_cmd, cmd1), sub_cmd1, NULL, "help for sub_cmd1",
			sub_cmd1_handler, 1, 0);
```

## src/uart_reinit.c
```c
/*
 * Copyright (c) 2021 Nordic Semiconductor ASA
 *
 * SPDX-License-Identifier: Apache-2.0
 */
#include <zephyr/shell/shell.h>
#include <zephyr/shell/shell_uart.h>
#include <zephyr/drivers/uart.h>
#include <zephyr/device.h>

void shell_init_from_work(struct k_work *work)
{
	const struct device *const dev = DEVICE_DT_GET(DT_CHOSEN(zephyr_shell_uart));
	bool log_backend = CONFIG_SHELL_BACKEND_SERIAL_LOG_LEVEL > 0;
	uint32_t level =
		(CONFIG_SHELL_BACKEND_SERIAL_LOG_LEVEL > LOG_LEVEL_DBG) ?
		CONFIG_LOG_MAX_LEVEL : CONFIG_SHELL_BACKEND_SERIAL_LOG_LEVEL;

	shell_init(shell_backend_uart_get_ptr(), dev,
		   shell_backend_uart_get_ptr()->ctx->cfg.flags,
		   log_backend, level);
}

static void shell_reinit_trigger(void)
{
	static struct k_work shell_init_work;

	k_work_init(&shell_init_work, shell_init_from_work);
	int err = k_work_submit(&shell_init_work);

	(void)err;
	__ASSERT_NO_MSG(err >= 0);
}

static void direct_uart_callback(const struct device *dev, void *user_data)
{
	static uint8_t buf[1];
	static bool tx_busy;

	uart_irq_update(dev);


	if (uart_irq_rx_ready(dev)) {
		while (uart_fifo_read(dev, buf, sizeof(buf))) {
			if (!tx_busy) {
				uart_irq_tx_enable(dev);
			}
		}
	}

	if (uart_irq_tx_ready(dev)) {
		if (!tx_busy) {
			(void)uart_fifo_fill(dev, buf, sizeof(buf));
			tx_busy = true;
		} else {
			tx_busy = false;
			uart_irq_tx_disable(dev);
			if (buf[0] == 'x') {
				uart_irq_rx_disable(dev);
				shell_reinit_trigger();
			}
		}
	}
}

static void uart_poll_timer_stopped(struct k_timer *timer)
{
	shell_reinit_trigger();
}

static void uart_poll_timeout(struct k_timer *timer)
{
	unsigned char c;
	const struct device *dev = k_timer_user_data_get(timer);

	while (uart_poll_in(dev, &c) == 0) {
		if (c != 'x') {
			uart_poll_out(dev, c);
		} else {
			k_timer_stop(timer);
		}
	}
}

K_TIMER_DEFINE(uart_poll_timer, uart_poll_timeout, uart_poll_timer_stopped);

static void shell_uninit_cb(const struct shell *sh, int res)
{
	__ASSERT_NO_MSG(res >= 0);
	const struct device *const dev = DEVICE_DT_GET(DT_CHOSEN(zephyr_shell_uart));

	if (IS_ENABLED(CONFIG_SHELL_BACKEND_SERIAL_INTERRUPT_DRIVEN)) {
		/* connect uart to my handler */
		uart_irq_callback_user_data_set(dev, direct_uart_callback, NULL);
		uart_irq_rx_enable(dev);
	} else {
		k_timer_user_data_set(&uart_poll_timer, (void *)dev);
		k_timer_start(&uart_poll_timer, K_MSEC(10), K_MSEC(10));
	}
}

static int cmd_uart_release(const struct shell *sh, size_t argc, char **argv)
{
	ARG_UNUSED(argc);
	ARG_UNUSED(argv);

	if (sh != shell_backend_uart_get_ptr()) {
		shell_error(sh, "Command dedicated for shell over uart");
		return -EINVAL;
	}

	shell_print(sh, "Uninitializing shell, use 'x' to reinitialize");
	shell_uninit(sh, shell_uninit_cb);

	return 0;
}

SHELL_CMD_REGISTER(shell_uart_release, NULL,
		"Uninitialize shell instance and release uart, start loopback "
		"on uart. Shell instance is reinitialized when 'x' is pressed",
		cmd_uart_release);
```
